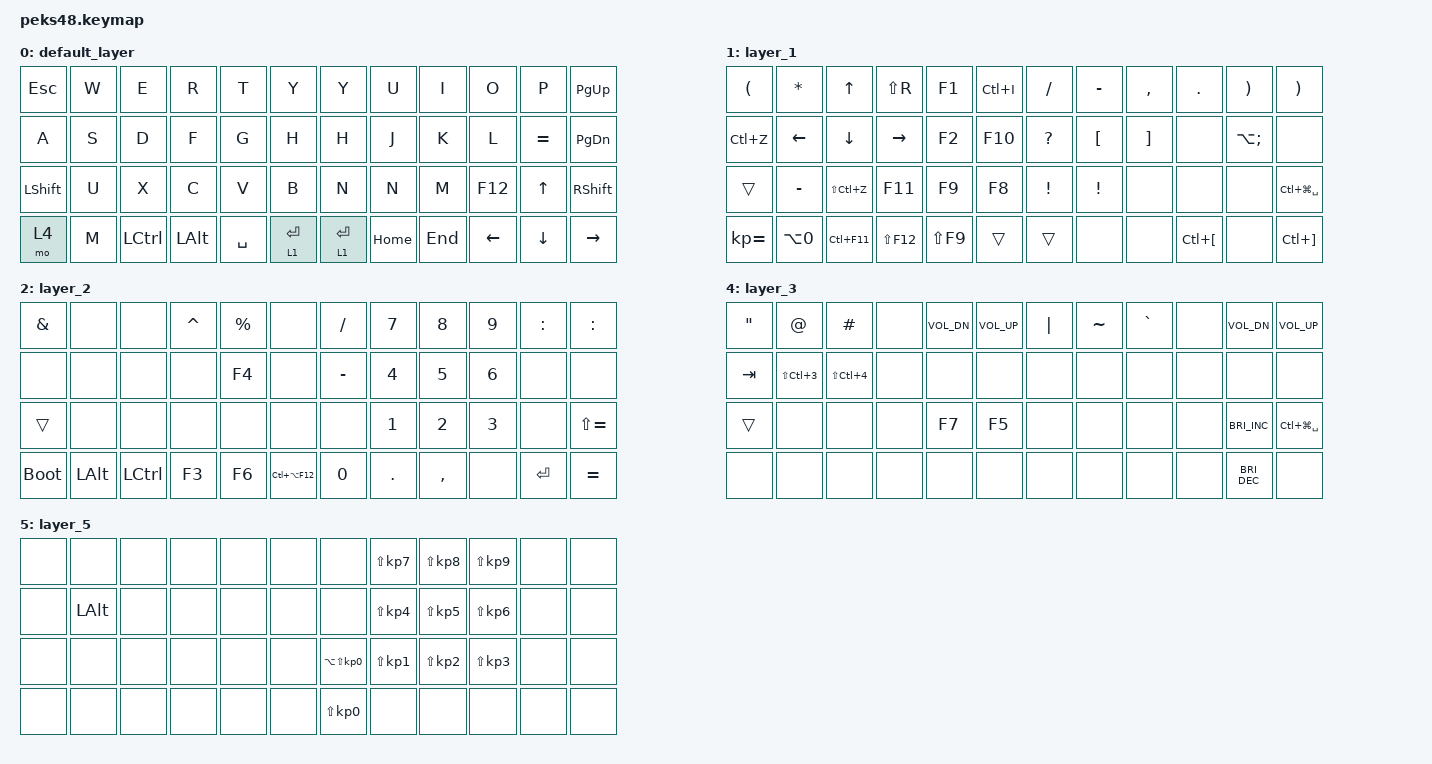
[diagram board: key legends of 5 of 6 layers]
#include <input/processors.dtsi>
#include <dt-bindings/zmk/input_transform.h>
#include <zephyr/dt-bindings/input/input-event-codes.h>
#include <behaviors.dtsi>
#include <dt-bindings/zmk/bt.h>
#include <dt-bindings/zmk/keys.h>

// Conversion definition for using Japanese keyboard with OS settings

#define JP_DQUOTE       AT                // "
#define JP_AMPERSAND    CARET             // &
#define JP_QUOTE        AMPERSAND         // '
#define JP_EQUAL        UNDER             // =
#define JP_CARET        EQUAL             // ^
#define JP_YEN          0x89              // ¥
#define JP_PLUS         COLON             // +
#define JP_TILDE        PLUS              // ~
#define JP_PIPE         LS(0x89)          // |
#define JP_AT           LEFT_BRACKET      // @
#define JP_COLON        SINGLE_QUOTE      // :
#define JP_ASTERISK     DOUBLE_QUOTES     // *
#define JP_BACKQUOTE    LEFT_BRACE        // `
#define JP_UNDERSCORE   LS(0x87)          // _
#define JP_LBRACKET     RIGHT_BRACKET     // [
#define JP_RBRACKET     BACKSLASH         // ]
#define JP_LPAREN       ASTERISK          // (
#define JP_RPAREN       LEFT_PARENTHESIS  // )
#define JP_LBRACE       RIGHT_BRACE       // {
#define JP_RBRACE       PIPE              // }
#define JP_KANA         LANGUAGE_1        // かな
#define JP_EISU         LANGUAGE_2        // 英数
#define JP_HANZEN       GRAVE             // 半角/全角

&mt {
    flavor = "balanced";
    quick-tap-ms = <0>;
    tapping-term-ms = <130>;
};

&lt { tapping-term-ms = <130>; };

/ {
    combos {
        compatible = "zmk,combos";

        q {
            bindings = <&kp Q>;
            key-positions = <0 1>;
            layers = <0>;
            timeout-ms = <100>;
        };

        L_bk {
            bindings = <&kp BACKSPACE>;
            key-positions = <1 2>;
            timeout-ms = <65>;
            layers = <0>;
        };

        MO2 {
            bindings = <&mo 2>;
            key-positions = <13 14>;
            timeout-ms = <90>;
            layers = <0>;
        };

        z {
            bindings = <&kp Z>;
            key-positions = <12 13>;
            timeout-ms = <65>;
            layers = <0>;
        };

        long {
            bindings = <&kp MINUS>;
            key-positions = <42 7>;
            timeout-ms = <120>;
            layers = <0>;
        };

        caps {
            bindings = <&kp LANG2>;
            key-positions = <8 9>;
            timeout-ms = <40>;
            layers = <0>;
        };

        kana {
            bindings = <&kp LANG1>;
            key-positions = <22 42>;
            timeout-ms = <70>;
            layers = <0>;
        };

        R_bk {
            bindings = <&kp BACKSPACE>;
            key-positions = <11 10>;
            timeout-ms = <60>;
            layers = <0>;
        };

        R_bk2 {
            bindings = <&kp BACKSPACE>;
            key-positions = <10 9>;
            timeout-ms = <60>;
            layers = <0>;
        };

        ble {
            bindings = <&mo 3>;
            key-positions = <11 10 9>;
            timeout-ms = <85>;
            layers = <0>;
        };

        f12 {
            bindings = <&kp LC(F12)>;
            key-positions = <41 40 39>;
            timeout-ms = <80>;
            layers = <0>;
        };

        n {
            bindings = <&kp N>;
            key-positions = <40 15>;
            timeout-ms = <90>;
            layers = <0>;
        };

        j {
            bindings = <&kp J>;
            key-positions = <17 16>;
            timeout-ms = <100>;
            layers = <0>;
        };

        o {
            bindings = <&kp O>;
            key-positions = <4 5>;
            timeout-ms = <80>;
            layers = <0>;
        };

        fn+j {
            bindings = <&kp LEFT_BRACKET>;
            key-positions = <17 16 15>;
            layers = <0>;
            timeout-ms = <100>;
        };

        p {
            bindings = <&kp P>;
            key-positions = <5 41>;
            timeout-ms = <85>;
            layers = <0>;
        };

        ctrl {
            bindings = <&kp LGUI>;
            key-positions = <41 40>;
            layers = <0>;
            timeout-ms = <85>;
        };

        shift+num {
            bindings = <&mo 5>;
            key-positions = <14 15>;
            timeout-ms = <85>;
            layers = <0>;
        };
    };

    keymap {
        compatible = "zmk,keymap";

        default_layer {
            bindings = <
&kp ESC     &kp W  &kp E      &kp R     &kp T      &kp Y          &kp Y        &kp U     &kp I    &kp O           &kp P           &kp PAGE_UP
&kp A       &kp S  &kp D      &kp F     &kp G      &kp H          &kp H        &kp J     &kp K    &kp L           &kp EQUAL       &kp PAGE_DOWN
&kp LSHIFT  &kp U  &kp X      &kp C     &kp V      &kp B          &kp N        &kp N     &kp M    &kp F12         &kp UP_ARROW    &kp RIGHT_SHIFT
&mo 4       &kp M  &kp LCTRL  &kp LALT  &kp SPACE  &lt 1 ENTER    &lt 1 ENTER  &kp HOME  &kp END  &kp LEFT_ARROW  &kp DOWN_ARROW  &kp RIGHT_ARROW
            >;
        };

        layer_1 {
            bindings = <
&kp LEFT_PARENTHESIS  &kp ASTRK   &kp UP_ARROW   &kp LS(R)    &kp F1      &kp LC(I)    &kp SLASH        &kp MINUS         &kp COMMA          &kp PERIOD            &kp RIGHT_PARENTHESIS  &kp RIGHT_PARENTHESIS
&kp LC(Z)             &kp LEFT    &kp DOWN       &kp RIGHT    &kp F2      &kp F10      &kp QUESTION     &kp LEFT_BRACKET  &kp RIGHT_BRACKET  &none                 &kp LA(SEMI)           &none
&trans                &kp MINUS   &kp LS(LC(Z))  &kp F11      &kp F9      &kp F8       &kp EXCLAMATION  &kp EXCLAMATION   &none              &none                 &none                  &kp LC(LG(SPACE))
&kp KP_EQUAL          &kp LA(N0)  &kp LC(F11)    &kp LS(F12)  &kp LS(F9)  &trans       &trans           &none             &none              &kp LC(LEFT_BRACKET)  &none                  &kp LC(RIGHT_BRACKET)
            >;
        };

        layer_2 {
            bindings = <
&kp AMPERSAND  &none         &none      &kp CARET  &kp PERCENT  &none              &kp SLASH  &kp N7        &kp N8        &kp N9        &kp COLON  &kp COLON
&none          &none         &none      &none      &kp F4       &none              &kp MINUS  &kp NUMBER_4  &kp N5        &kp NUMBER_6  &none      &none
&trans         &none         &none      &none      &none        &none              &none      &kp NUMBER_1  &kp NUMBER_2  &kp NUMBER_3  &none      &kp LS(EQUAL)
&bootloader    &kp LEFT_ALT  &kp LCTRL  &kp F3     &kp F6       &kp LC(LA(F12))    &kp N0     &kp DOT       &kp COMMA     &none         &kp ENTER  &kp EQUAL
            >;
        };

        ble {
            bindings = <
&bt BT_SEL 0  &bt BT_SEL 1  &bt BT_SEL 2  &bt BT_SEL 3  &bt BT_SEL 4  &none    &none        &none  &none  &none  &none  &none
&none         &none         &none         &none         &none         &none    &none        &none  &none  &none  &none  &none
&bootloader   &none         &none         &none         &none         &none    &bootloader  &none  &none  &none  &none  &bt BT_CLR
&bootloader   &none         &none         &none
            >;
        };

        layer_3 {
            bindings = <
&kp DOUBLE_QUOTES  &kp AT                &kp HASH              &none  &kp C_VOL_DN  &kp C_VOL_UP    &kp PIPE  &kp TILDE  &kp GRAVE  &none  &kp C_VOL_DN          &kp C_VOL_UP
&kp TAB            &kp LS(LC(NUMBER_3))  &kp LS(LC(NUMBER_4))  &none  &none         &none           &none     &none      &none      &none  &none                 &none
&trans             &none                 &none                 &none  &kp F7        &kp F5          &none     &none      &none      &none  &kp C_BRIGHTNESS_INC  &kp LC(LG(SPACE))
&none              &none                 &none                 &none  &none         &none           &none     &none      &none      &none  &kp C_BRIGHTNESS_DEC  &none
            >;
        };

        layer_5 {
            bindings = <
&none  &none     &none  &none  &none  &none    &none                    &kp LS(KP_NUMBER_7)  &kp LS(KP_NUMBER_8)  &kp LS(KP_NUMBER_9)  &none  &none
&none  &kp LALT  &none  &none  &none  &none    &none                    &kp LS(KP_NUMBER_4)  &kp LS(KP_NUMBER_5)  &kp LS(KP_NUMBER_6)  &none  &none
&none  &none     &none  &none  &none  &none    &kp LA(LS(KP_NUMBER_0))  &kp LS(KP_NUMBER_1)  &kp LS(KP_NUMBER_2)  &kp LS(KP_NUMBER_3)  &none  &none
&none  &none     &none  &none  &none  &none    &kp LS(KP_N0)            &none                &none                &none                &none  &none
            >;
        };
    };
};
